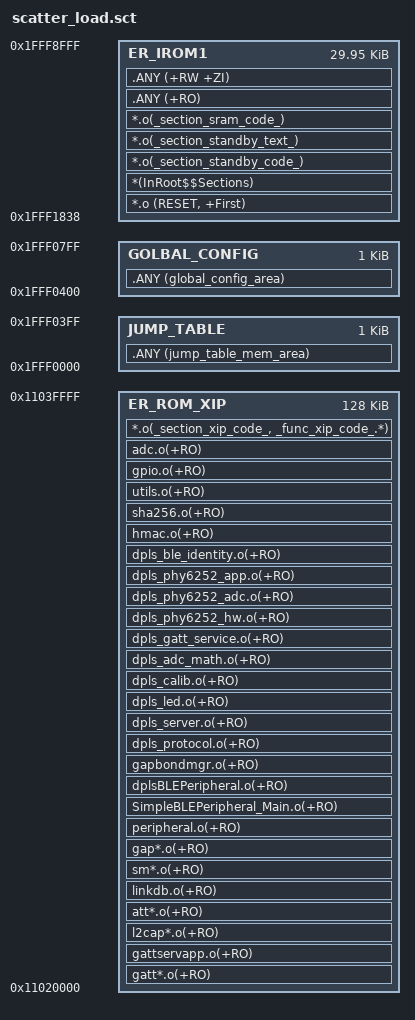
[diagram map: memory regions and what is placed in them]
; Test-DPLS PHY6252 memory map.
; Production code keeps startup/sleep-critical code and RW/ZI in retained SRAM,
; while application/host code executes from flash XIP. The SDK demo's DTM-only
; SRAM2 region is intentionally absent: production main has no RF direct-test
; entry point and P20 belongs exclusively to the +1 ADC input.

LR_IROM1 0x1fff1838 0x0E7C8 {
  ER_IROM1 0x1fff1838 0x077C8 {
    *.o (RESET, +First)
    *(InRoot$$Sections)
    *.o(_section_standby_code_)
    *.o(_section_standby_text_)
    *.o(_section_sram_code_)
    .ANY (+RO)
    .ANY (+RW +ZI)
  }
}

LR_ROM_JT_GC 0x1fff0000 0x00800 {
  JUMP_TABLE 0x1fff0000 0x00400 {
    .ANY (jump_table_mem_area)
  }
  GOLBAL_CONFIG 0x1fff0400 0x00400 {
    .ANY (global_config_area)
  }
}

LR_ROM_XIP 0x11020000 0x020000 {
  ER_ROM_XIP 0x11020000 0x020000 {
    gatt*.o(+RO)
    gattservapp.o(+RO)
    l2cap*.o(+RO)
    att*.o(+RO)
    linkdb.o(+RO)
    sm*.o(+RO)
    gap*.o(+RO)
    peripheral.o(+RO)
    SimpleBLEPeripheral_Main.o(+RO)
    dplsBLEPeripheral.o(+RO)
    gapbondmgr.o(+RO)
    dpls_protocol.o(+RO)
    dpls_server.o(+RO)
    dpls_led.o(+RO)
    dpls_calib.o(+RO)
    dpls_adc_math.o(+RO)
    dpls_gatt_service.o(+RO)
    dpls_phy6252_hw.o(+RO)
    dpls_phy6252_adc.o(+RO)
    dpls_phy6252_app.o(+RO)
    dpls_ble_identity.o(+RO)
    hmac.o(+RO)
    sha256.o(+RO)
    utils.o(+RO)
    gpio.o(+RO)
    adc.o(+RO)
    *.o(_section_xip_code_, _func_xip_code_.*)
  }
}
